# nrf7140_wificore register map
Vendor: Nordic Semiconductor; Series: nRF71; File version: 1
Registers are 32-bit, read-write, reset 0x0 unless marked. A register's access mark holds for its fields unless they carry their own. Offsets are from the block's base; [hi:lo] are bit positions; lines under a group give offsets from that group; {n}, {i} and the like mark numbered series; 'fields as' and 'values as' point back to an identical list.

## RPUSYS (part 3 of 3) — RPUPBUS
Base 0x48080000; alternate view of RPUMAC
0x1A000 WLAN_TIMERS group — Unspecified
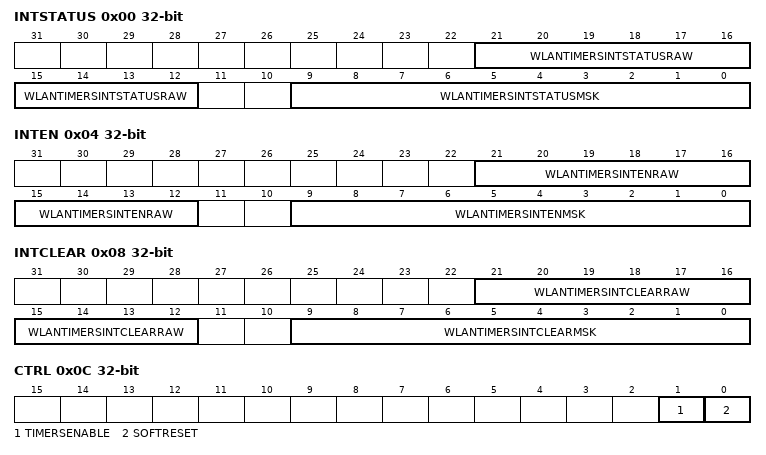
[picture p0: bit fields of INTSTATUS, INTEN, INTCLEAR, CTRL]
  0x00 INTSTATUS — WLAN TIMERS INT STATUS
    [21:12] WLANTIMERSINTSTATUSRAW — General purpose raw interrupt status register.
    [9:0] WLANTIMERSINTSTATUSMSK — General purpose masked interrupt status register.
  0x04 INTEN — WLAN TIMERS INT EN
    [21:12] WLANTIMERSINTENRAW — General purpose raw interrupt enable register.
    [9:0] WLANTIMERSINTENMSK — General purpose masked interrupt enable register.
  0x08 INTCLEAR — WLAN TIMERS INT CLEAR
    [21:12] WLANTIMERSINTCLEARRAW — General purpose raw interrupt clear register.
    [9:0] WLANTIMERSINTCLEARMSK — General purpose masked interrupt clear register.
  0x0C CTRL — WLAN TIMERS CTRL
    [1] TIMERSENABLE — Timers module enable/disable.0: Disable1: Enable
    [0] SOFTRESET — Timers core soft reset.This bit is used to reset everything but the control registers.The soft reset should be applied after reprogramming the control registers and setting TIMERS_ENABLE.0: De-assert reset to core1: Assert reset to core
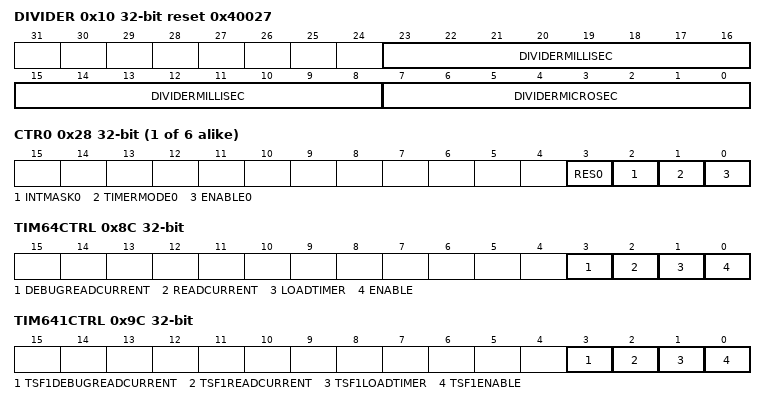
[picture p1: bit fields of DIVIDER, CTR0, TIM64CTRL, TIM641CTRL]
  0x10 DIVIDER reset 0x40027 — WLAN TIMERS DIVIDER
    [23:8] DIVIDERMILLISEC — Timers millisecond divider.NOTE: In the current implementation, when the milli second counter has reached the value 0x1,and the micro second counter has reached 0x0, then on the occurence of the enxt 40MHz clock pulsethe milli second counter is initialised to the DIVIDER_MILLI_SEC field value.
    [7:0] DIVIDERMICROSEC — Timers microsecond divider.
  {0x20+0x10*j} TIM{j} reset 0xFFFFFF (j=0..5) — WLAN TIMERS TIM{j}
    [23:0] INITTIMER{j} — Timer {j} initial value, 24-bit.
  {0x24+0x10*j} CURTIM{j} ro reset 0xFFFFFF (j=0..5) — WLAN TIMERS CUR TIM{j}
    [23:0] CURTIMER{j} — Current timer {j} value, 24-bit.
  {0x28+0x10*j} CTR{j} (j=0..5) — WLAN TIMERS CTR{j}
    [3] RES{j} — Resolution bit.0: 1 us1: 1 ms
    [2] INTMASK{j} — Interrupt Mask.0: Unmasked - Generates Interrupts1: Masked - Masks Interrupts
    [1] TIMERMODE{j} — Timer mode.0: Free-running (periodic). Starts with programmed value, counts down to zero and restarts again from programmed value.When the counter reaches zero, it generates an interrupt.1: One-Shot mode - Starts with programmed value, counts down to zero and stops.When the counter reaches zero, it generates an interrupt.
    [0] ENABLE{j} — Enable timer.0: Disabled1: Enabled
  0x80 TIM64LSB — WLAN TIMERS TIM64 LSB
    [23:0] INITTIMER230 — TSF Timer register for the 32 least significant bits.Write: Initial timer value, lower 32-bits.Read:Current timer value, lower 32-bits.
  0x84 TIM64MIDSB — WLAN TIMERS TIM64 MIDSB
    [23:0] INITTIMER4724 — TSF Timer register for the 32 middle significant bits.Write: Initial timer value, middle 32-bits.Read:Current timer value, middle 32-bits.
  0x88 TIM64MSB — WLAN TIMERS TIM64 MSB
    [15:0] INITTIMER6348 — TSF Timer register for the 16 most significant bits.Write: Initial timer value, higher 32-bits.Read:Current timer value, higher 32-bits.
  0x8C TIM64CTRL — WLAN TIMERS TIM64 CTRL
    [3] DEBUGREADCURRENT — For Debugging purposes.
      0=Functionality disabled (default value); 1=Every clock cycle read back the current value of the TSF timer
    [2] READCURRENT — Write '1' to update current timer value in WLAN_TIMERS_TIM64_MSB, WLAN_TIMERS_TIM64_MIDSB and WLAN_TIMERS_TIM64_LSB registers.
    [1] LOADTIMER — Write '1' to load timer with initial value.
    [0] ENABLE — Enable timer. 0: Disabled 1: Enabled
  0x90 TIM641LSB — WLAN TIMERS TIM64 1 LSB
    [23:0] INITTIMER1230 — TSF1 Timer register for the 24 least significant bits.Write: Initial timer value, lower 24-bits.Read:Current timer value, lower 24-bits.
  0x94 TIM641MIDSB — WLAN TIMERS TIM64 1 MIDSB
    [23:0] INITTIMER14724 — TSF1 Timer register for the 24 middle significant bits.Write: Initial timer value, middle 24-bits.Read:Current timer value, middle 24-bits.
  0x98 TIM641MSB — WLAN TIMERS TIM64 1 MSB
    [15:0] INITTIMER16348 — TSF1 Timer register for the 16 most significant bits.Write: Initial timer value, higher 16-bits.Read:Current timer value, higher 16-bits.
  0x9C TIM641CTRL — WLAN TIMERS TIM64 1 CTRL
    [3] TSF1DEBUGREADCURRENT — For Debugging purposes.
      0=Functionality disabled (default value); 1=Every clock cycle read back the current value of the TSF1 timer
    [2] TSF1READCURRENT — Write '1' to update current timer value in WLAN_TIMERS_TIM64_1_MSB, WLAN_TIMERS_TIM64_1_MIDSB and WLAN_TIMERS_TIM64_1_LSB registers.
    [1] TSF1LOADTIMER — Write '1' to load timer with initial value.
    [0] TSF1ENABLE — Enable timer. 0: Disabled 1: Enabled
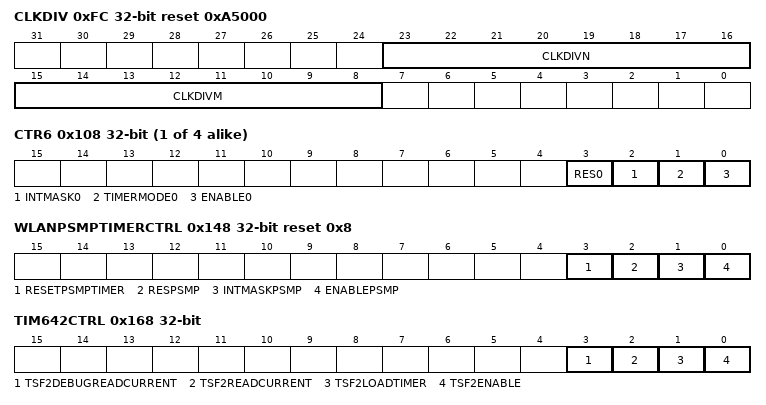
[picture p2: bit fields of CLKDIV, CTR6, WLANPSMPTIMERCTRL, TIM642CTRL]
  0xFC CLKDIV reset 0xA5000 — WLAN TIMERS CLK DIV
    [23:16] CLKDIVN — The frequency of the clock source for the milli/micro-second clock divider is F x N / M = 40MHz, where F is the core clock frequency. Can only act as a divider, not as a multiplier, and the ratio N/M must be less than or equal to 1/2.
    [15:8] CLKDIVM — The frequency of the clock source for the milli/micro-second clock divider is F x N / M = 40MHz, where F is the core clock frequency. Can only act as a divider, not as a multiplier, and the ratio N/M must be less than or equal to 1/2.
  {0xA0+0x10*j} TIM{j} reset 0xFFFFFF (j=6..9) — WLAN TIMERS TIM{j}
    [23:0] INITTIMER{j} — Timer {j} initial value, 24-bit.
  {0xA4+0x10*j} CURTIM{j} ro reset 0xFFFFFF (j=6..9) — WLAN TIMERS CUR TIM{j}
    [23:0] CURTIMER{j} — Current timer {j} value, 24-bit.
  {0xA8+0x10*j} CTR{j} (j=6..9) — WLAN TIMERS CTR{j}
    fields as WLAN_TIMERS.CTR0
  0x140 WLANPSMPTIMERTIM
    [23:0] TARGETPSMPTIME — PSMP Timer timeout value, 24-bit. PSMP timer generates interrupt on reaching this value.
  0x144 WLANPSMPTIMERCUR ro
    [23:0] PSMPCURTIME — Current timer value, 24-bit.
  0x148 WLANPSMPTIMERCTRL reset 0x8
    [3] RESETPSMPTIMER — Reset timer.** NOTE: After reset, Reset_enable bit will be set. Thus timer will be in reset mode.
      0=ResetDisable; 1=Reset enable,Timer will be in reset mode , header decoded signal will be ignored
    [2] RESPSMP — Resolution bit.0: 1 us1: 1 ms
    [1] INTMASKPSMP — Interrupt Mask0: Unmasked - Generates Interrupts1: Masked - Masks Interrupts
    [0] ENABLEPSMP — Enable timer.** NOTE: After reset, Enable_timer bit will be cleared. Thus timer will not be enabled.
      0=Disabled; 1=Enabled
  0x14C WLANPSMPTIMERINITIALVALUE
    [23:0] PSMPINITVALUE — A write to this register loads the initial Load value into the PSMP timer.
  0x150 PRIMCCA20ELAPSEDTIME — WLAN TIMERS PRIM CCA20 ELAPSED TIME
    [23:0] PRIMCCA20ELAPSEDTIME — This field returns the latched value of the delta timer on the falling edge ofthe primary 20 CCA signal.
  0x154 SECCCA20ELAPSEDTIME — WLAN TIMERS SEC CCA20 ELAPSED TIME
    [23:0] SECCCA20ELAPSEDTIME — This field returns the latched value of the delta timer on the falling edge ofthe secondary 20 CCA signal.
  0x158 SECCCA40ELAPSEDTIME — WLAN TIMERS SEC CCA40 ELAPSED TIME
    [23:0] SECCCA40ELAPSEDTIME — This field returns the latched value of the delta timer on the falling edge ofthe secondary 40 CCA signal.
  0x15C TIM642LSB — WLAN TIMERS TIM64 2 LSB
    [23:0] INITTIMER2230 — TSF2 Timer register for the 24 least significant bits.Write: Initial timer value, lower 24-bits.Read:Current timer value, lower 24-bits.
  0x160 TIM642MIDSB — WLAN TIMERS TIM64 2 MIDSB
    [23:0] INITTIMER24724 — TSF2 Timer register for the 24 middle significant bits.Write: Initial timer value, middle 24-bits.Read:Current timer value, middle 24-bits.
  0x164 TIM642MSB — WLAN TIMERS TIM64 2 MSB
    [15:0] INITTIMER26348 — TSF2 Timer register for the 16 most significant bits.Write: Initial timer value, higher 16-bits.Read:Current timer value, higher 16-bits.
  0x168 TIM642CTRL — WLAN TIMERS TIM64 2 CTRL
    [3] TSF2DEBUGREADCURRENT — For Debugging purposes.
      0=Functionality disabled (default value); 1=Every clock cycle read back the current value of the TSF2 timer
    [2] TSF2READCURRENT — Write '1' to update current timer value in WLAN_TIMERS_TIM64_2_MSB, WLAN_TIMERS_TIM64_2_MIDSB and WLAN_TIMERS_TIM64_2_LSB registers.
    [1] TSF2LOADTIMER — Write '1' to load timer with initial value.
    [0] TSF2ENABLE — Enable timer. 0: Disabled 1: Enabled
  0x16C TIM643LSB — WLAN TIMERS TIM64 3 LSB
    [23:0] INITTIMER3230 — TSF3 Timer register for the 24 least significant bits.Write: Initial timer value, lower 24-bits.Read:Current timer value, lower 24-bits.
  0x170 TIM643MIDSB — WLAN TIMERS TIM64 3 MIDSB
    [23:0] INITTIMER34724 — TSF3 Timer register for the 24 middle significant bits.Write: Initial timer value, middle 24-bits.Read:Current timer value, middle 24-bits.
  0x174 TIM643MSB — WLAN TIMERS TIM64 3 MSB
    [15:0] INITTIMER36348 — TSF Timer register for the 16 most significant bits.Write: Initial timer value, higher 16-bits.Read:Current timer value, higher 16-bits.
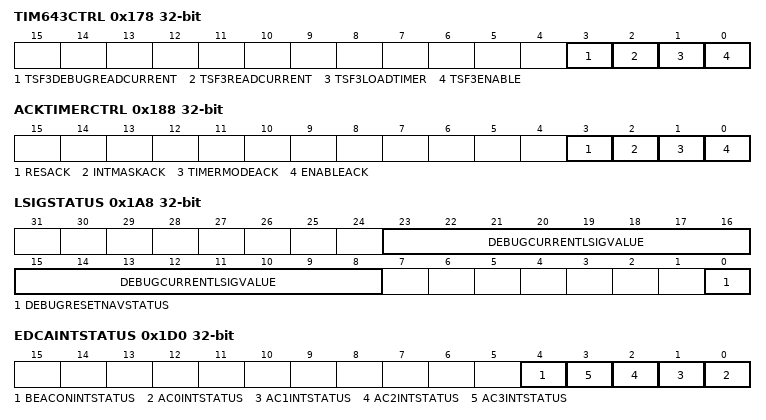
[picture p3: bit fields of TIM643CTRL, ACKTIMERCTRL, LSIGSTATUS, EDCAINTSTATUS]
  0x178 TIM643CTRL — WLAN TIMERS TIM64 3 CTRL
    [3] TSF3DEBUGREADCURRENT — For Debugging purposes.
      0=Functionality disabled (default value); 1=Every clock cycle read back the current value of the TSF3 timer
    [2] TSF3READCURRENT — Write '1' to update current timer value in WLAN_TIMERS_TIM64_3_MSB, WLAN_TIMERS_TIM64_3_MIDSB and WLAN_TIMERS_TIM64_3_LSB registers.
    [1] TSF3LOADTIMER — Write '1' to load timer with initial value.
    [0] TSF3ENABLE — Enable timer. 0: Disabled 1: Enabled
  0x180 ACKTIMER reset 0xFFFFFF — WLAN TIMERS ACK TIMER
    [23:0] WLANTIMERSACKTIMER — Timer initial value.
  0x184 ACKCURTIM ro reset 0xFFFFFF — WLAN TIMERS ACK CUR TIM
    [23:0] WLANTIMERSACKCURTIM — Acknowledgement timer current value.
  0x188 ACKTIMERCTRL — WLAN TIMERS ACK TIMER CTRL
    [3] RESACK — Resolution bit.0: 1 us1: 1 ms
    [2] INTMASKACK — Interrupt Mask.0: Unmasked - Generates Interrupts1: Masked - Masks Interrupts
    [1] TIMERMODEACK — Timer mode.0: Free-running (periodic). Starts with programmed value, counts down to zero and restarts again from programmed value.When the counter reaches zero, it generates an interrupt.1: One-Shot mode - Starts with programmed value, counts down to zero and stops.When the counter reaches zero, it generates an interrupt.
    [0] ENABLEACK — Enable timer.0: Disabled1: Enabled
  0x194 PERIPLSIGTIMER — WLAN TIMERS PERIP LSIG TIMER
    [15:0] LSIGTIMER — LSIG value, configured by MCP.
  0x198 PERIPCHLOAD — WLAN TIMERS PERIP CH LOAD
    [0] CHLOADENABLE — Channel load timer enable bit.1: channel load enable0: channel load disable.Note MCU needs to configure channel load register to zero before setting enable register.
  0x19C PERIPCHANNELLOAD — WLAN TIMERS PERIP CHANNEL LOAD
    [23:0] CHLOADTIMERVALUE — Indicates channel load in microsecods.
  0x1A0 PERIPDELTACURTIM reset 0xFFFFFF — WLAN TIMERS PERIP DELTA CUR TIM
    [23:0] CURTIMER — Current timer value.Writing to this register causes the timer to start counting from the written value, otherwise it continues counting, wrapping at 0.
  0x1A4 PERIPDELTACTRL — WLAN TIMERS PERIP DELTA CTRL
    [0] DELTAENABLE — Enable timer.0: Disabled1: Enabled
  0x1A8 LSIGSTATUS — WLAN TIMERS LSIG STATUS
    [23:8] DEBUGCURRENTLSIGVALUE — A read of this field returns the current LSig Timer value.
    [0] DEBUGRESETNAVSTATUS — When the LSIG counter transitions from 0x1 to 0x0, then this bit is set to indicatethat the LSIG timer has reached zero from its preloaded value.NOTE: A write to this register then clears the bit.
  0x1B0 ACKINTSTATUS — WLAN TIMERS ACK INT STATUS
    [1:0] ACKINTSTATUS — Interrupt status of ACK timer.[0] - Masked Interrupt Status of ACK timer.[1] - Raw Interrupt status of ACK Timer.
  0x1B8 ACKINTEN — WLAN TIMERS ACK INT EN
    [1:0] ACKINTEN — Enable ACK timer interrupt.[0] - Enable Masked ACK Timer interrupt.[1] - Enable Raw ACK Timer interrupt.
  0x1BC ACKINTCLEAR — WLAN TIMERS ACK INT CLEAR
    [1:0] ACKINTCLEAR — [0] - Writing '1' to this field clears the masked ACK timer interrupt.[1] - Writing '1' to this field clears the raw ACK timer interrupt.
  0x1C0 PSMPINTSTATUS — WLAN TIMERS PSMP INT STATUS
    [1:0] PSMPINTSTATUS — [0] - Masked Interrupt status of PSMP timer.[1] - Raw Interrupt status of PSMP timer.
  0x1C4 PSMPINTEN — WLAN TIMERS PSMP INT EN
    [1:0] PSMPINTEN — [0] - Enable masked interrupt of PSMP timer.[1] - Enable raw interrupt of PSMP timer.
  0x1C8 PSMPINTCLEAR — WLAN TIMERS PSMP INT CLEAR
    [1:0] PSMPINTCLEAR — [0] - Writing '1' to this field clears the masked PSMP timer interrupt.[1] - Writing '1' to this field clears the raw PSMP timer interrupt.
  0x1D0 EDCAINTSTATUS — WLAN TIMERS EDCA INT STATUS
    [4] BEACONINTSTATUS — Masked Interrupt status of BEACON timer.
    [n] AC{n}INTSTATUS (n=0..3) — Masked Interrupt status of AC{n} timer.
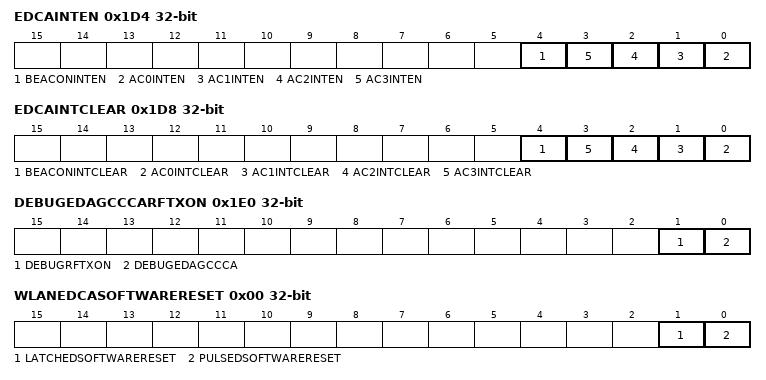
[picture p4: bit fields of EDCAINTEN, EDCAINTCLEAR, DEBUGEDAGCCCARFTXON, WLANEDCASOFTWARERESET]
  0x1D4 EDCAINTEN — WLAN TIMERS EDCA INT EN
    [4] BEACONINTEN — Interrupt enable of BEACON timer.
    [n] AC{n}INTEN (n=0..3) — Interrupt enable of AC{n} timer.
  0x1D8 EDCAINTCLEAR — WLAN TIMERS EDCA INT CLEAR
    [4] BEACONINTCLEAR — Writing '1' to this field clears interrupt of BEACON timer.
    [n] AC{n}INTCLEAR (n=0..3) — Writing '1' to this field clears interrupt of AC{n} timer.
  0x1DC DEBUGMODE
    [0] DEBUGMODE — Debug register to set debug mode of EDCA timer.
  0x1E0 DEBUGEDAGCCCARFTXON
    [1] DEBUGRFTXON — Debug register for rf_tx_on input of EDCA timer.
    [0] DEBUGEDAGCCCA — Debug register for edagc_cca input of EDCA timer.
  0x1E4 DEBUGNAVCOUNTERNONZERO ro
    [0] DEBUGNAVCOUNTERNONZERO — Debug register for nav_counter_non_zero output of EDCA timer.
0x1A200 WIFICORETIMERSEDCA group — Unspecified
  0x00 WLANEDCASOFTWARERESET
    [1] LATCHEDSOFTWARERESET
    [0] PULSEDSOFTWARERESET — Self-clearing software reset
  0x04 WLANEDCAINTRSTATUSEN
    [4:0] WLANEDCAINTRSTATUSEN — Enables Wlan EDCA Intr Status
  0x08 WLANEDCAINTRSTATUS
    [4:0] WLANEDCAINTRSTATUS — Updates Status of Channel winBit 0 - Status of Channel 0 winBit 1 - Status of Channel 1 winBit 2 - Status of Channel 2 winBit 3 - Status of Channel 3 winBit 4 - Status of Channel 4 win
  0x0C WLANEDCAFEATURESENABLE
    [0] WLANEDCAFEATURESENABLE — BackOff number is set to WLAN_EDCA_BACKOFF_NUMBER of corresponding AC
  0x10 WLANEDCADEACTIVATE reset 0x1
    [0] WLANEDCADEACTIVATE — System goes to IN_ACTIVE state
  0x14 WLANEDCASLOTTIME
    [15:0] WLANEDCASLOTTIME — Set EDCA Slot time
  0x18 WLANEDCASTARTUPCOMPENSATION
    [15:0] WLANEDCASTARTUPCOMPENSATION — Startup compensation value
  {0x1C+4j} WLANEDCACWAC{j} (j=0..4)
    [3:0] WLANEDCACWAC{j} — Wlan EDCA CWindow AC{j}
  0x30 WLANEDCAAIFSNXSLOTPLUSSIFSAC0 reset 0x4F
    [9:0] WLANEDCAAIFSNXSLOTPLUSSIFSAC0 — Default AC0(AC_BK)=79; AIFSN = 7; SLOT_TIME(11a/g)= 9usec ; SIFS= 16usec
  0x34 WLANEDCAAIFSNXSLOTPLUSSIFSAC1 reset 0x2B
    [9:0] WLANEDCAAIFSNXSLOTPLUSSIFSAC1 — Default AC1(AC_BE)=43; AIFSN = 3; SLOT_TIME(11a/g)= 9usec ; SIFS= 16usec
  0x38 WLANEDCAAIFSNXSLOTPLUSSIFSAC2 reset 0x22
    [9:0] WLANEDCAAIFSNXSLOTPLUSSIFSAC2 — Default AC2(AC_VI)=34; AIFSN = 2; SLOT_TIME(11a/g)= 9usec ; SIFS= 16usec
  0x3C WLANEDCAAIFSNXSLOTPLUSSIFSAC3 reset 0x22
    [9:0] WLANEDCAAIFSNXSLOTPLUSSIFSAC3 — Default AC3(AC_VO)=34; AIFSN = 2; SLOT_TIME(11a/g)= 9usec ; SIFS= 16usec
  0x40 WLANEDCAAIFSNXSLOTPLUSSIFSAC4 reset 0x1C
    [9:0] WLANEDCAAIFSNXSLOTPLUSSIFSAC4 — Beacon PIFS = ( SIFS + 1 * SLOT_TIME)
  {0x44+4j} WLANEDCABACKOFFNUMBERAC{j} (j=0..4)
    [23:0] WLANEDCABACKOFFNUMBERAC{j} — Set BackOff Number for AC{j} from Register
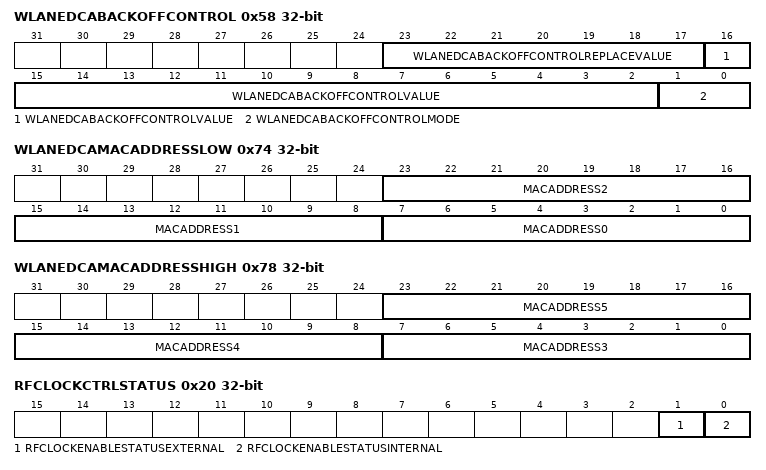
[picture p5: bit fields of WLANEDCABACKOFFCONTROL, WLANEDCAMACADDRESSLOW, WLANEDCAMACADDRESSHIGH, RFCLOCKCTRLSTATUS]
  0x58 WLANEDCABACKOFFCONTROL
    [23:17] WLANEDCABACKOFFCONTROLREPLACEVALUE — If BACKOFF_CONTROL_OPERATION_LIMIT_CHECK_AND_REPLACE is set,replace backOffNumber from WLAN_EDCA_BACKOFF_CONTROL(Bit's B17 to B23) ifbackOffNumber is greater than WLAN_EDCA_BACKOFF_CONTROL(Bit's B2 to B16)
    [16:2] WLANEDCABACKOFFCONTROLVALUE — 1. If BACKOFF_CONTROL_OPERATION_ADD is set, Add value preset in WLAN_EDCA_BACKOFF_CONTROL (Bit's B2 to B16 ) to backOffNumber2. If BACKOFF_CONTROL_OPERATION_SUB is set, subtract backOffNumber from WLAN_EDCA_BACKOFF_CONTROL(Bit's B2 to B16) ifbackOffNumber is greater than equal to WLAN_EDCA_BACKOFF_CONTROL(Bit's B2 to B16) else replace backOffNumber withWLAN_EDCA_BACKOFF_CONTROL (Bit's B2 to B16)3. If BACKOFF_CONTROL_OPERATION_LIMIT_CHECK_AND_REPLACE is set, replace backOffNumber from WLAN_EDCA_BACKOFF_CONTROL(Bit's B17 to B23) ifbackOffNumber is greater than WLAN_EDCA_BACKOFF_CONTROL(Bit's B2 to B16)
    [1:0] WLANEDCABACKOFFCONTROLMODE — Set EDCA BackOff Control to add/sub/replace mode
  0x5C WLANEDCAINTRABSSNAVTIMER reset 0x1
    [23:0] INTRABSSNAVTIMER
  0x60 WLANEDCAINTERBSSNAVTIMER reset 0x1
    [23:0] INTERBSSNAVTIMER
  0x64 WLANEDCASIFSAFTERCCABUSY
    [23:0] WLANEDCASIFSAFTERCCABUSY — Turnaround time when state goes to CCA_BUSY
  0x68 WLANEDCASIFSAFTERINTERNAVBUSY
    [23:0] WLANEDCASIFSAFTERINTERNAVBUSY — Turnaround time when state goes to INTER_NAV_BUSY
  0x6C WLANEDCASIFSAFTERINTRANAVBUSY
    [23:0] WLANEDCASIFSAFTERINTRANAVBUSY — Turnaround time when state goes to INTRA_NAV_BUSY
  0x70 WLANEDCASIFSAFTERTXON
    [23:0] WLANEDCASIFSAFTERTXON — Turnaround time when state goes to TX_ON
  0x74 WLANEDCAMACADDRESSLOW
    [23:16] MACADDRESS2 — MAC_ADDRESS 3rd byte
    [15:8] MACADDRESS1 — MAC_ADDRESS 2nd byte
    [7:0] MACADDRESS0 — MAC_ADDRESS 1st byte
  0x78 WLANEDCAMACADDRESSHIGH
    [23:16] MACADDRESS5 — MAC_ADDRESS 6th byte
    [15:8] MACADDRESS4 — MAC_ADDRESS 5th byte
    [7:0] MACADDRESS3 — MAC_ADDRESS 4th byte
  0x7C WLANEDCACCABUSYMEASUREMENTDURATION
    [23:0] CCABUSYMEASUREMENTDURATION
  0x80 WLANEDCACCABUSYDURATION
    [23:0] WLANEDCACCABUSYDURATION — EDCA CCA busy duration
  0x84 WLANEDCANAVBUSYMEASUREMENTDURATION
    [23:0] NAVBUSYMEASUREMENTDURATION
  0x88 WLANEDCANAVBUSYDURATION
    [23:0] WLANEDCANAVBUSYDURATION — EDCA NAV busy duration
  {0x8C+4j} WLANEDCASUSPENDEDCAFTIMERAC{j} (j=0..4)
    [23:0] WLANEDCASUSPENDEDCAFTIMERAC{j} — EDCA Suspend EDCAF timer
  {0xD4+4j} WLANEDCADEBUGAIFSAC{j} ro (j=0..4)
    [23:0] WLANEDCADEBUGAIFSAC{j} — Debug register to monitor AIFS of AC{j}
  0xE8 WLANEDCADEBUGSUSPENDEDACSTATUS ro
    [4:0] WLANEDCADEBUGSUSPENDEDACSTATUS — Debug Suspended AC status
  0xEC WLANEDCADEBUGINTERBSSNAVTIMER ro
    [23:0] WLANEDCADEBUGINTERBSSNAVTIMER — Debug interBssNavTimer_rg
  0xF0 WLANEDCADEBUGINTRABSSNAVTIMER ro
    [23:0] WLANEDCADEBUGINTRABSSNAVTIMER — Debug intraBssNavTimer_rg
  0xF4 WLANEDCADEBUGCCABUSYMEASUREMENTDURATION ro
    [23:0] WLANEDCADEBUGCCABUSYMEASUREMENTDURATION — Debug CCA busy measurement duration
  0xF8 WLANEDCADEBUGFSMSTATE ro
    [7:0] WLANEDCADEBUGFSMSTATE — Debug FSM State
  0xFC WLANEDCADEBUGFREEZEFSMDURINGPBUSWRITES
    [0] DEBUGFREEZEFSMDURINGPBUSWRITES
0x1B000 WIFICORECLOCKRESETCTRL group — Unspecified
  0x00 CLOCKGATECTRLCLOCKENABLESTATUSALL ro
    [0] CLOCKENABLESTATUSALL — Status of all clocks.
      0=SomeClocksDisabled; 1=AllClocksActive
  0x04 CLOCKGATECTRLCLOCKENABLESETALL
    [0] CLOCKENABLESETALL — Enable all clocks.
      0=NoAction; 1=EnableAllClocks
  0x08 CLOCKGATECTRLCLOCKENABLECLRALL
    [0] CLOCKENABLECLRALL — Disable all clocks.
      0=NoAction; 1=DisableAllClocks
  0x20 RFCLOCKCTRLSTATUS ro
    [1] RFCLOCKENABLESTATUSEXTERNAL — Status of the External RF clock.
      0=External RF Clock disabled; 1=External RF Clock enabled
    [0] RFCLOCKENABLESTATUSINTERNAL — Status of the Internal RF clock.
      0=Internal RF Clock disabled; 1=Internal RF Clock enabled
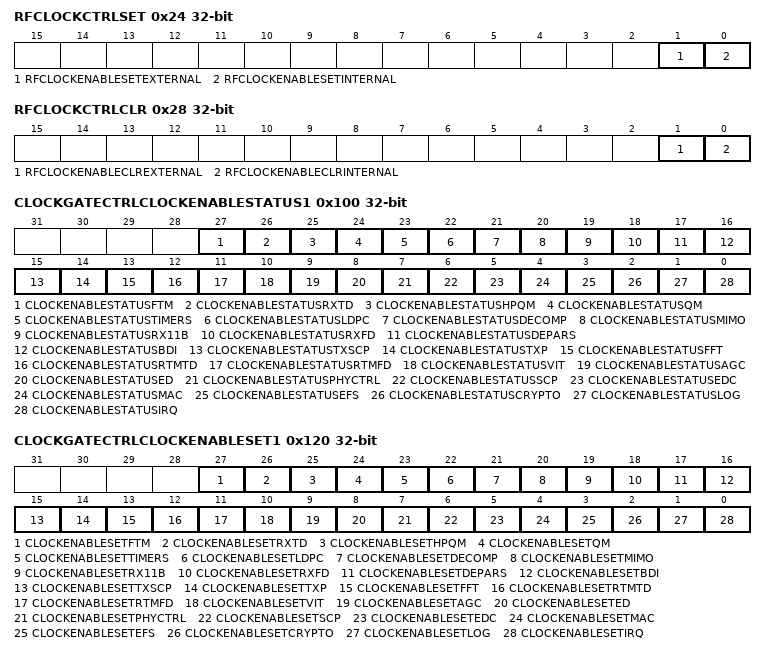
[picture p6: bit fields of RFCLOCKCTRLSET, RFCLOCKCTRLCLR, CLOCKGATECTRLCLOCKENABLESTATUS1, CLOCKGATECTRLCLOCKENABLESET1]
  0x24 RFCLOCKCTRLSET
    [1] RFCLOCKENABLESETEXTERNAL — Enable the External RF clock.
      0=NoAction; 1=Enable External RF clock
    [0] RFCLOCKENABLESETINTERNAL — Enable the Internal RF clock.
      0=NoAction; 1=Enable Internal RF clock
  0x28 RFCLOCKCTRLCLR
    [1] RFCLOCKENABLECLREXTERNAL — Enable the External RF clock.
      0=NoAction; 1=Disable External RF clock
    [0] RFCLOCKENABLECLRINTERNAL — Disable the Internal RF clock.
      0=NoAction; 1=Disable Internal RF clock
  0x38 UPSCALEWIFIREQ
    [0] UPSCALEWIFIREQ — Request upscaled 1.1V supply for Wi-Fi.
      0=DonTRequest; 1=Request
  0x3C UPSCALEWIFIACK ro
    [0] UPSCALEWIFIACK — Acknowledgment for upscaled 1.1V supply request for Wi-Fi.
      0=Request not acknowledged; 1=RequestAcknowledged
  0x100 CLOCKGATECTRLCLOCKENABLESTATUS1 ro
    [all] fields
      0=ClockDisabled; 1=ClockActive
    [27] CLOCKENABLESTATUSFTM — Status of the FTM clock.
    [26] CLOCKENABLESTATUSRXTD — Status of the RXTD clock.
    [25] CLOCKENABLESTATUSHPQM — Status of the HPQM clock.
    [24] CLOCKENABLESTATUSQM — Status of the QM clock.
    [23] CLOCKENABLESTATUSTIMERS — Status of the TIMERS clock.
    [22] CLOCKENABLESTATUSLDPC — Status of the LDPC clock.
    [21] CLOCKENABLESTATUSDECOMP — Status of the DECOMP clock.
    [20] CLOCKENABLESTATUSMIMO — Status of the MIMO clock.
    [19] CLOCKENABLESTATUSRX11B — Status of the RX11B clock.
    [18] CLOCKENABLESTATUSRXFD — Status of the RXFD clock.
    [17] CLOCKENABLESTATUSDEPARS — Status of the DEPARS clock.
    [16] CLOCKENABLESTATUSBDI — Status of the BDI clock.
    [15] CLOCKENABLESTATUSTXSCP — Status of the TXSCP clock.
    [14] CLOCKENABLESTATUSTXP — Status of the TXP clock.
    [13] CLOCKENABLESTATUSFFT — Status of the FFT clock.
    [12] CLOCKENABLESTATUSRTMTD — Status of the RTMTD clock.
    [11] CLOCKENABLESTATUSRTMFD — Status of the RTMFD clock.
    [10] CLOCKENABLESTATUSVIT — Status of the VIT clock.
    [9] CLOCKENABLESTATUSAGC — Status of the AGC clock.
    [8] CLOCKENABLESTATUSED — Status of the ED clock.
    [7] CLOCKENABLESTATUSPHYCTRL — Status of the PHYCTRL clock.
    [6] CLOCKENABLESTATUSSCP — Status of the SCP clock.
    [5] CLOCKENABLESTATUSEDC — Status of the EDC clock.
    [4] CLOCKENABLESTATUSMAC — Status of the MAC clock.
    [3] CLOCKENABLESTATUSEFS — Status of the EFS clock.
    [2] CLOCKENABLESTATUSCRYPTO — Status of the CRYPTO clock.
    [1] CLOCKENABLESTATUSLOG — Status of the LOG clock.
    [0] CLOCKENABLESTATUSIRQ — Status of the IRQ clock.
  0x120 CLOCKGATECTRLCLOCKENABLESET1
    [all] fields
      0=NoAction; 1=EnableClock
    [27] CLOCKENABLESETFTM — Enable the FTM clock.
    [26] CLOCKENABLESETRXTD — Enable the RXTD clock.
    [25] CLOCKENABLESETHPQM — Enable the HPQM clock.
    [24] CLOCKENABLESETQM — Enable the QM clock.
    [23] CLOCKENABLESETTIMERS — Enable the TIMERS clock.
    [22] CLOCKENABLESETLDPC — Enable the LDPC clock.
    [21] CLOCKENABLESETDECOMP — Enable the DECOMP clock.
    [20] CLOCKENABLESETMIMO — Enable the MIMO clock.
    [19] CLOCKENABLESETRX11B — Enable the RX11B clock.
    [18] CLOCKENABLESETRXFD — Enable the RXFD clock.
    [17] CLOCKENABLESETDEPARS — Enable the DEPARS clock.
    [16] CLOCKENABLESETBDI — Enable the BDI clock.
    [15] CLOCKENABLESETTXSCP — Enable the TXSCP clock.
    [14] CLOCKENABLESETTXP — Enable the TXP clock.
    [13] CLOCKENABLESETFFT — Enable the FFT clock.
    [12] CLOCKENABLESETRTMTD — Enable the RTMTD clock.
    [11] CLOCKENABLESETRTMFD — Enable the RTMFD clock.
    [10] CLOCKENABLESETVIT — Enable the VIT clock.
    [9] CLOCKENABLESETAGC — Enable the AGC clock.
    [8] CLOCKENABLESETED — Enable the ED clock.
    [7] CLOCKENABLESETPHYCTRL — Enable the PHYCTRL clock.
    [6] CLOCKENABLESETSCP — Enable the SCP clock.
    [5] CLOCKENABLESETEDC — Enable the EDC clock.
    [4] CLOCKENABLESETMAC — Enable the MAC clock.
    [3] CLOCKENABLESETEFS — Enable the EFS clock.
    [2] CLOCKENABLESETCRYPTO — Enable the CRYPTO clock.
    [1] CLOCKENABLESETLOG — Enable the LOG clock.
    [0] CLOCKENABLESETIRQ — Enable the IRQ clock.
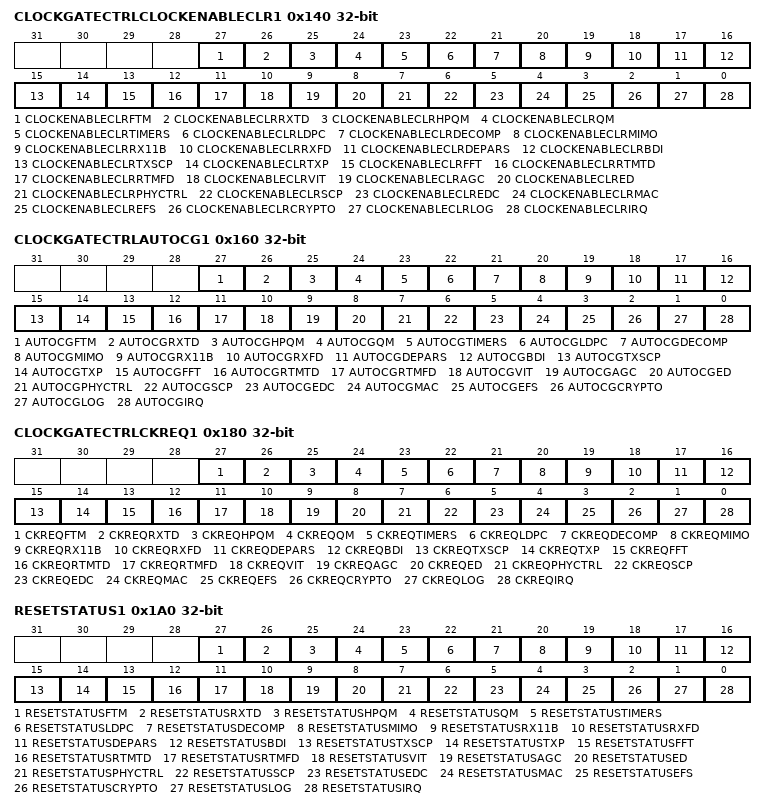
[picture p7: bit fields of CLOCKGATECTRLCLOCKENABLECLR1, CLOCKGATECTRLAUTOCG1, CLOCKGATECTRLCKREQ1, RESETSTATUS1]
  0x140 CLOCKGATECTRLCLOCKENABLECLR1
    [all] fields
      0=NoAction; 1=DisableClock
    [27] CLOCKENABLECLRFTM — Disable the FTM clock.
    [26] CLOCKENABLECLRRXTD — Disable the RXTD clock.
    [25] CLOCKENABLECLRHPQM — Disable the HPQM clock.
    [24] CLOCKENABLECLRQM — Disable the QM clock.
    [23] CLOCKENABLECLRTIMERS — Disable the TIMERS clock.
    [22] CLOCKENABLECLRLDPC — Disable the LDPC clock.
    [21] CLOCKENABLECLRDECOMP — Disable the DECOMP clock.
    [20] CLOCKENABLECLRMIMO — Disable the MIMO clock.
    [19] CLOCKENABLECLRRX11B — Disable the RX11B clock.
    [18] CLOCKENABLECLRRXFD — Disable the RXFD clock.
    [17] CLOCKENABLECLRDEPARS — Disable the DEPARS clock.
    [16] CLOCKENABLECLRBDI — Disable the BDI clock.
    [15] CLOCKENABLECLRTXSCP — Disable the TXSCP clock.
    [14] CLOCKENABLECLRTXP — Disable the TXP clock.
    [13] CLOCKENABLECLRFFT — Disable the FFT clock.
    [12] CLOCKENABLECLRRTMTD — Disable the RTMTD clock.
    [11] CLOCKENABLECLRRTMFD — Disable the RTMFD clock.
    [10] CLOCKENABLECLRVIT — Disable the VIT clock.
    [9] CLOCKENABLECLRAGC — Disable the AGC clock.
    [8] CLOCKENABLECLRED — Disable the ED clock.
    [7] CLOCKENABLECLRPHYCTRL — Disable the PHYCTRL clock.
    [6] CLOCKENABLECLRSCP — Disable the SCP clock.
    [5] CLOCKENABLECLREDC — Disable the EDC clock.
    [4] CLOCKENABLECLRMAC — Disable the MAC clock.
    [3] CLOCKENABLECLREFS — Disable the EFS clock.
    [2] CLOCKENABLECLRCRYPTO — Disable the CRYPTO clock.
    [1] CLOCKENABLECLRLOG — Disable the LOG clock.
    [0] CLOCKENABLECLRIRQ — Disable the IRQ clock.
  0x160 CLOCKGATECTRLAUTOCG1
    [all] fields
      0=Automatic clock-gating disabled; 1=AutomaticClockGatin1 (Automatic clock-gating enabled.)
    [27] AUTOCGFTM — Enable automatic clock-gating of the FTM clock.
    [26] AUTOCGRXTD — Enable automatic clock-gating of the RXTD clock.
    [25] AUTOCGHPQM — Enable automatic clock-gating of the HPQM clock.
    [24] AUTOCGQM — Enable automatic clock-gating of the QM clock.
    [23] AUTOCGTIMERS — Enable automatic clock-gating of the TIMERS clock.
    [22] AUTOCGLDPC — Enable automatic clock-gating of the LDPC clock.
    [21] AUTOCGDECOMP — Enable automatic clock-gating of the DECOMP clock.
    [20] AUTOCGMIMO — Enable automatic clock-gating of the MIMO clock.
    [19] AUTOCGRX11B — Enable automatic clock-gating of the RX11B clock.
    [18] AUTOCGRXFD — Enable automatic clock-gating of the RXFD clock.
    [17] AUTOCGDEPARS — Enable automatic clock-gating of the DEPARS clock.
    [16] AUTOCGBDI — Enable automatic clock-gating of the BDI clock.
    [15] AUTOCGTXSCP — Enable automatic clock-gating of the TXSCP clock.
    [14] AUTOCGTXP — Enable automatic clock-gating of the TXP clock.
    [13] AUTOCGFFT — Enable automatic clock-gating of the FFT clock.
    [12] AUTOCGRTMTD — Enable automatic clock-gating of the RTMTD clock.
    [11] AUTOCGRTMFD — Enable automatic clock-gating of the RTMFD clock.
    [10] AUTOCGVIT — Enable automatic clock-gating of the VIT clock.
    [9] AUTOCGAGC — Enable automatic clock-gating of the AGC clock.
    [8] AUTOCGED — Enable automatic clock-gating of the ED clock.
    [7] AUTOCGPHYCTRL — Enable automatic clock-gating of the PHYCTRL clock.
    [6] AUTOCGSCP — Enable automatic clock-gating of the SCP clock.
    [5] AUTOCGEDC — Enable automatic clock-gating of the EDC clock.
    [4] AUTOCGMAC — Enable automatic clock-gating of the MAC clock.
    [3] AUTOCGEFS — Enable automatic clock-gating of the EFS clock.
    [2] AUTOCGCRYPTO — Enable automatic clock-gating of the CRYPTO clock.
    [1] AUTOCGLOG — Enable automatic clock-gating of the LOG clock.
    [0] AUTOCGIRQ — Enable automatic clock-gating of the IRQ clock.
  0x180 CLOCKGATECTRLCKREQ1 ro
    [all] fields
      0=ClockDisabled; 1=ClockActive
    [27] CKREQFTM — Status of the FTM clock request.
    [26] CKREQRXTD — Status of the RXTD clock request.
    [25] CKREQHPQM — Status of the HPQM clock request.
    [24] CKREQQM — Status of the QM clock request.
    [23] CKREQTIMERS — Status of the TIMERS clock request.
    [22] CKREQLDPC — Status of the LDPC clock request.
    [21] CKREQDECOMP — Status of the DECOMP clock request.
    [20] CKREQMIMO — Status of the MIMO clock request.
    [19] CKREQRX11B — Status of the RX11B clock request.
    [18] CKREQRXFD — Status of the RXFD clock request.
    [17] CKREQDEPARS — Status of the DEPARS clock request.
    [16] CKREQBDI — Status of the BDI clock request.
    [15] CKREQTXSCP — Status of the TXSCP clock request.
    [14] CKREQTXP — Status of the TXP clock request.
    [13] CKREQFFT — Status of the FFT clock request.
    [12] CKREQRTMTD — Status of the RTMTD clock request.
    [11] CKREQRTMFD — Status of the RTMFD clock request.
    [10] CKREQVIT — Status of the VIT clock request.
    [9] CKREQAGC — Status of the AGC clock request.
    [8] CKREQED — Status of the ED clock request.
    [7] CKREQPHYCTRL — Status of the PHYCTRL clock request.
    [6] CKREQSCP — Status of the SCP clock request.
    [5] CKREQEDC — Status of the EDC clock request.
    [4] CKREQMAC — Status of the MAC clock request.
    [3] CKREQEFS — Status of the EFS clock request.
    [2] CKREQCRYPTO — Status of the CRYPTO clock request.
    [1] CKREQLOG — Status of the LOG clock request.
    [0] CKREQIRQ — Status of the IRQ clock request.
  0x1A0 RESETSTATUS1 ro
    [all] fields
      0=ResetDeasserted; 1=ResetAsserted
    [27] RESETSTATUSFTM — Status of the FTM reset.
    [26] RESETSTATUSRXTD — Status of the RXTD reset.
    [25] RESETSTATUSHPQM — Status of the HPQM reset.
    [24] RESETSTATUSQM — Status of the QM reset.
    [23] RESETSTATUSTIMERS — Status of the TIMERS reset.
    [22] RESETSTATUSLDPC — Status of the LDPC reset.
    [21] RESETSTATUSDECOMP — Status of the DECOMP reset.
    [20] RESETSTATUSMIMO — Status of the MIMO reset.
    [19] RESETSTATUSRX11B — Status of the RX11B reset.
    [18] RESETSTATUSRXFD — Status of the RXFD reset.
    [17] RESETSTATUSDEPARS — Status of the DEPARS reset.
    [16] RESETSTATUSBDI — Status of the BDI reset.
    [15] RESETSTATUSTXSCP — Status of the TXSCP reset.
    [14] RESETSTATUSTXP — Status of the TXP reset.
    [13] RESETSTATUSFFT — Status of the FFT reset.
    [12] RESETSTATUSRTMTD — Status of the RTMTD reset.
    [11] RESETSTATUSRTMFD — Status of the RTMFD reset.
    [10] RESETSTATUSVIT — Status of the VIT reset.
    [9] RESETSTATUSAGC — Status of the AGC reset.
    [8] RESETSTATUSED — Status of the ED reset.
    [7] RESETSTATUSPHYCTRL — Status of the PHYCTRL reset.
    [6] RESETSTATUSSCP — Status of the SCP reset.
    [5] RESETSTATUSEDC — Status of the EDC reset.
    [4] RESETSTATUSMAC — Status of the MAC reset.
    [3] RESETSTATUSEFS — Status of the EFS reset.
    [2] RESETSTATUSCRYPTO — Status of the CRYPTO reset.
    [1] RESETSTATUSLOG — Status of the LOG reset.
    [0] RESETSTATUSIRQ — Status of the IRQ reset.
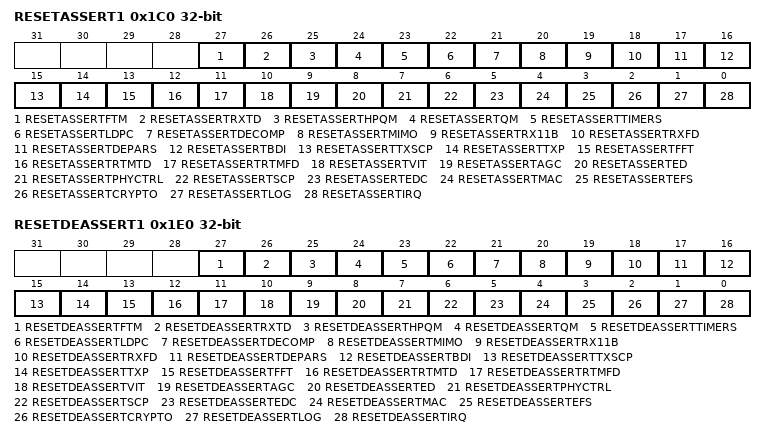
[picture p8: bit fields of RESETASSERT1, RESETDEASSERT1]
  0x1C0 RESETASSERT1
    [all] fields
      0=NoAction; 1=AssertReset
    [27] RESETASSERTFTM — Assert the FTM reset.
    [26] RESETASSERTRXTD — Assert the RXTD reset.
    [25] RESETASSERTHPQM — Assert the HPQM reset.
    [24] RESETASSERTQM — Assert the QM reset.
    [23] RESETASSERTTIMERS — Assert the TIMERS reset.
    [22] RESETASSERTLDPC — Assert the LDPC reset.
    [21] RESETASSERTDECOMP — Assert the DECOMP reset.
    [20] RESETASSERTMIMO — Assert the MIMO reset.
    [19] RESETASSERTRX11B — Assert the RX11B reset.
    [18] RESETASSERTRXFD — Assert the RXFD reset.
    [17] RESETASSERTDEPARS — Assert the DEPARS reset.
    [16] RESETASSERTBDI — Assert the BDI reset.
    [15] RESETASSERTTXSCP — Assert the TXSCP reset.
    [14] RESETASSERTTXP — Assert the TXP reset.
    [13] RESETASSERTFFT — Assert the FFT reset.
    [12] RESETASSERTRTMTD — Assert the RTMTD reset.
    [11] RESETASSERTRTMFD — Assert the RTMFD reset.
    [10] RESETASSERTVIT — Assert the VIT reset.
    [9] RESETASSERTAGC — Assert the AGC reset.
    [8] RESETASSERTED — Assert the ED reset.
    [7] RESETASSERTPHYCTRL — Assert the PHYCTRL reset.
    [6] RESETASSERTSCP — Assert the SCP reset.
    [5] RESETASSERTEDC — Assert the EDC reset.
    [4] RESETASSERTMAC — Assert the MAC reset.
    [3] RESETASSERTEFS — Assert the EFS reset.
    [2] RESETASSERTCRYPTO — Assert the CRYPTO reset.
    [1] RESETASSERTLOG — Assert the LOG reset.
    [0] RESETASSERTIRQ — Assert the IRQ reset.
  0x1E0 RESETDEASSERT1
    [all] fields
      0=NoAction; 1=DeassertReset
    [27] RESETDEASSERTFTM — Deassert the FTM reset.
    [26] RESETDEASSERTRXTD — Deassert the RXTD reset.
    [25] RESETDEASSERTHPQM — Deassert the HPQM reset.
    [24] RESETDEASSERTQM — Deassert the QM reset.
    [23] RESETDEASSERTTIMERS — Deassert the TIMERS reset.
    [22] RESETDEASSERTLDPC — Deassert the LDPC reset.
    [21] RESETDEASSERTDECOMP — Deassert the DECOMP reset.
    [20] RESETDEASSERTMIMO — Deassert the MIMO reset.
    [19] RESETDEASSERTRX11B — Deassert the RX11B reset.
    [18] RESETDEASSERTRXFD — Deassert the RXFD reset.
    [17] RESETDEASSERTDEPARS — Deassert the DEPARS reset.
    [16] RESETDEASSERTBDI — Deassert the BDI reset.
    [15] RESETDEASSERTTXSCP — Deassert the TXSCP reset.
    [14] RESETDEASSERTTXP — Deassert the TXP reset.
    [13] RESETDEASSERTFFT — Deassert the FFT reset.
    [12] RESETDEASSERTRTMTD — Deassert the RTMTD reset.
    [11] RESETDEASSERTRTMFD — Deassert the RTMFD reset.
    [10] RESETDEASSERTVIT — Deassert the VIT reset.
    [9] RESETDEASSERTAGC — Deassert the AGC reset.
    [8] RESETDEASSERTED — Deassert the ED reset.
    [7] RESETDEASSERTPHYCTRL — Deassert the PHYCTRL reset.
    [6] RESETDEASSERTSCP — Deassert the SCP reset.
    [5] RESETDEASSERTEDC — Deassert the EDC reset.
    [4] RESETDEASSERTMAC — Deassert the MAC reset.
    [3] RESETDEASSERTEFS — Deassert the EFS reset.
    [2] RESETDEASSERTCRYPTO — Deassert the CRYPTO reset.
    [1] RESETDEASSERTLOG — Deassert the LOG reset.
    [0] RESETDEASSERTIRQ — Deassert the IRQ reset.
